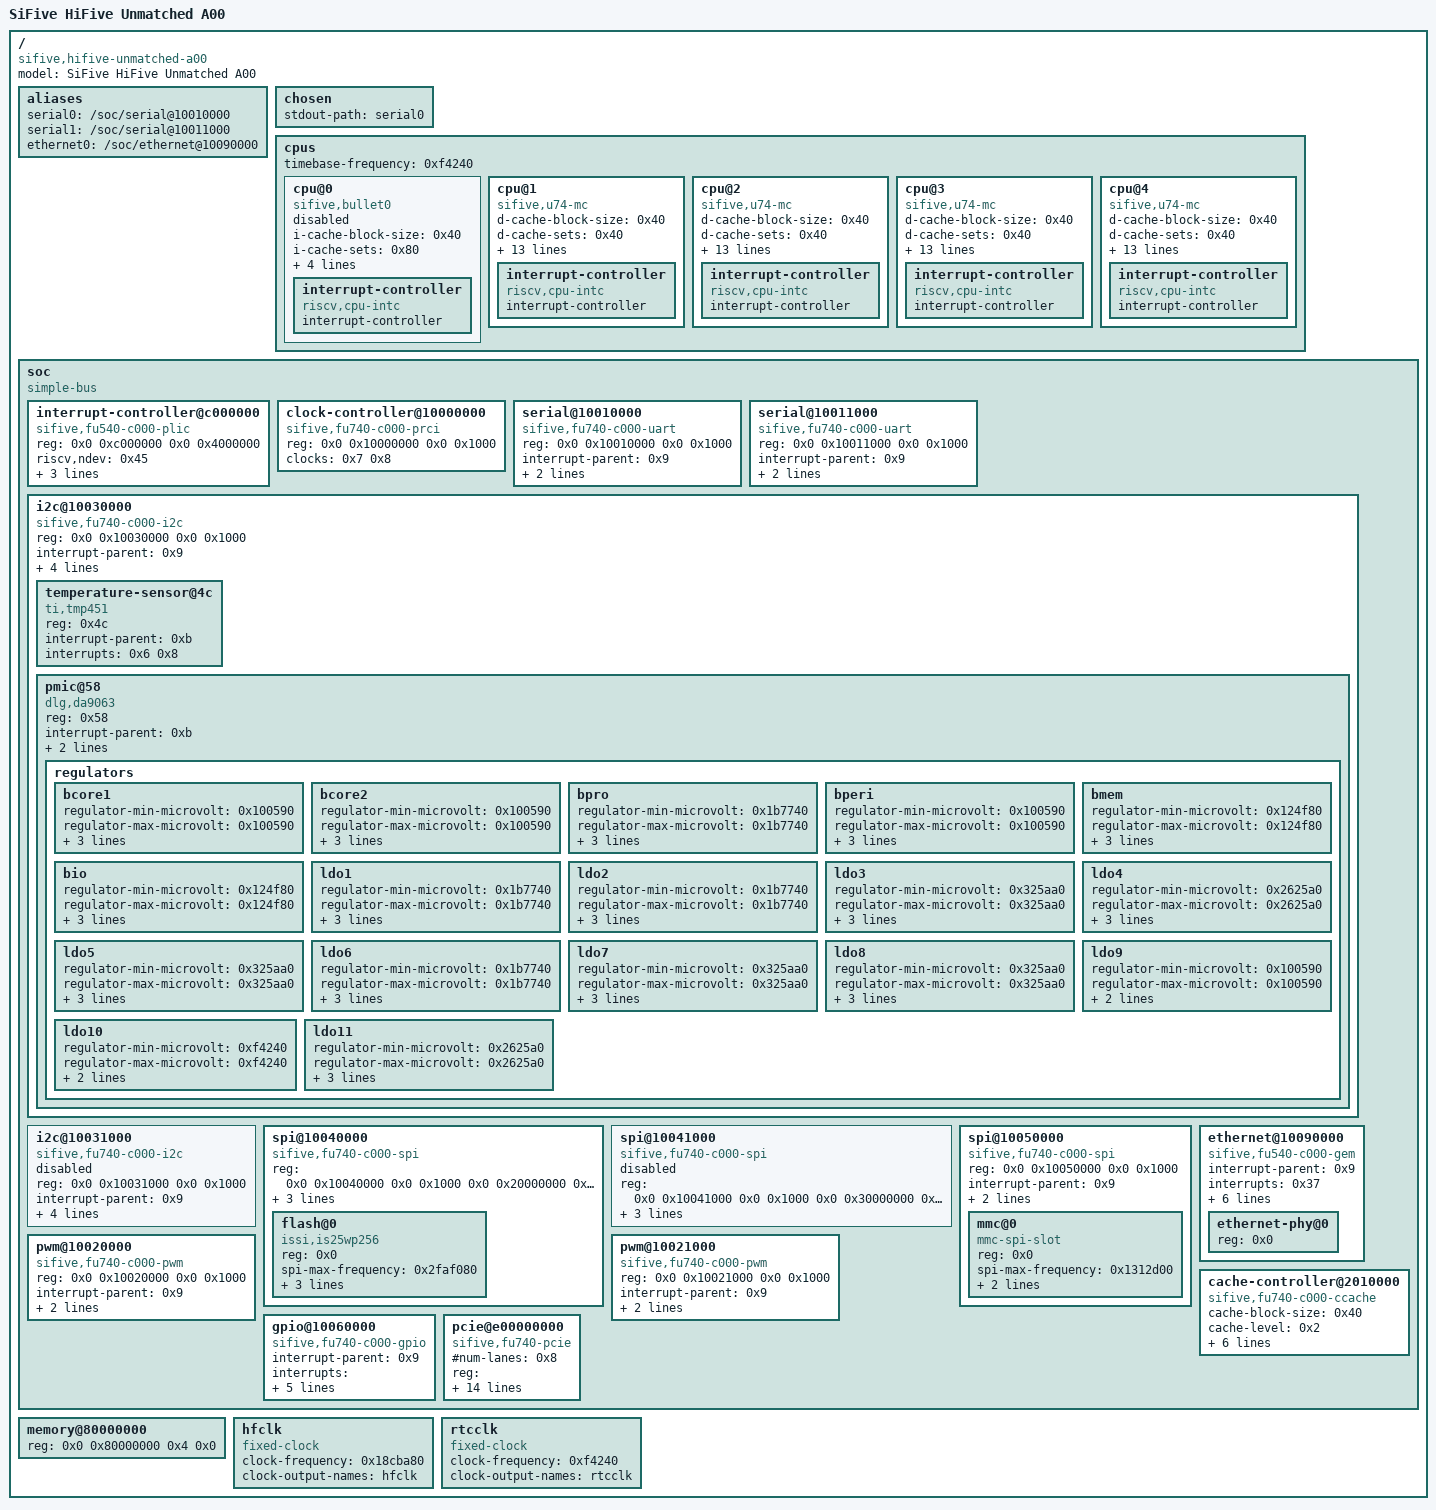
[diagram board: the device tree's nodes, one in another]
/dts-v1/;

/ {
	#address-cells = <0x2>;
	#size-cells = <0x2>;
	compatible = "sifive,hifive-unmatched-a00", "sifive,fu740-c000", "sifive,fu740";
	model = "SiFive HiFive Unmatched A00";

	aliases {
		serial0 = "/soc/serial@10010000";
		serial1 = "/soc/serial@10011000";
		ethernet0 = "/soc/ethernet@10090000";
	};

	chosen {
		stdout-path = "serial0";
	};

	cpus {
		#address-cells = <0x1>;
		#size-cells = <0x0>;
		timebase-frequency = <0xf4240>;

		cpu@0 {
			compatible = "sifive,bullet0", "riscv";
			device_type = "cpu";
			i-cache-block-size = <0x40>;
			i-cache-sets = <0x80>;
			i-cache-size = <0x4000>;
			next-level-cache = <0x1>;
			reg = <0x0>;
			riscv,isa = "rv64imac";
			status = "disabled";

			interrupt-controller {
				#interrupt-cells = <0x1>;
				compatible = "riscv,cpu-intc";
				interrupt-controller;
				phandle = <0x2>;
			};
		};

		cpu@1 {
			compatible = "sifive,u74-mc", "sifive,bullet0", "riscv";
			d-cache-block-size = <0x40>;
			d-cache-sets = <0x40>;
			d-cache-size = <0x8000>;
			d-tlb-sets = <0x1>;
			d-tlb-size = <0x28>;
			device_type = "cpu";
			i-cache-block-size = <0x40>;
			i-cache-sets = <0x80>;
			i-cache-size = <0x8000>;
			i-tlb-sets = <0x1>;
			i-tlb-size = <0x28>;
			mmu-type = "riscv,sv39";
			next-level-cache = <0x1>;
			reg = <0x1>;
			riscv,isa = "rv64imafdc";
			tlb-split;

			interrupt-controller {
				#interrupt-cells = <0x1>;
				compatible = "riscv,cpu-intc";
				interrupt-controller;
				phandle = <0x3>;
			};
		};

		cpu@2 {
			compatible = "sifive,u74-mc", "sifive,bullet0", "riscv";
			d-cache-block-size = <0x40>;
			d-cache-sets = <0x40>;
			d-cache-size = <0x8000>;
			d-tlb-sets = <0x1>;
			d-tlb-size = <0x28>;
			device_type = "cpu";
			i-cache-block-size = <0x40>;
			i-cache-sets = <0x80>;
			i-cache-size = <0x8000>;
			i-tlb-sets = <0x1>;
			i-tlb-size = <0x28>;
			mmu-type = "riscv,sv39";
			next-level-cache = <0x1>;
			reg = <0x2>;
			riscv,isa = "rv64imafdc";
			tlb-split;

			interrupt-controller {
				#interrupt-cells = <0x1>;
				compatible = "riscv,cpu-intc";
				interrupt-controller;
				phandle = <0x4>;
			};
		};

		cpu@3 {
			compatible = "sifive,u74-mc", "sifive,bullet0", "riscv";
			d-cache-block-size = <0x40>;
			d-cache-sets = <0x40>;
			d-cache-size = <0x8000>;
			d-tlb-sets = <0x1>;
			d-tlb-size = <0x28>;
			device_type = "cpu";
			i-cache-block-size = <0x40>;
			i-cache-sets = <0x80>;
			i-cache-size = <0x8000>;
			i-tlb-sets = <0x1>;
			i-tlb-size = <0x28>;
			mmu-type = "riscv,sv39";
			next-level-cache = <0x1>;
			reg = <0x3>;
			riscv,isa = "rv64imafdc";
			tlb-split;

			interrupt-controller {
				#interrupt-cells = <0x1>;
				compatible = "riscv,cpu-intc";
				interrupt-controller;
				phandle = <0x5>;
			};
		};

		cpu@4 {
			compatible = "sifive,u74-mc", "sifive,bullet0", "riscv";
			d-cache-block-size = <0x40>;
			d-cache-sets = <0x40>;
			d-cache-size = <0x8000>;
			d-tlb-sets = <0x1>;
			d-tlb-size = <0x28>;
			device_type = "cpu";
			i-cache-block-size = <0x40>;
			i-cache-sets = <0x80>;
			i-cache-size = <0x8000>;
			i-tlb-sets = <0x1>;
			i-tlb-size = <0x28>;
			mmu-type = "riscv,sv39";
			next-level-cache = <0x1>;
			reg = <0x4>;
			riscv,isa = "rv64imafdc";
			tlb-split;

			interrupt-controller {
				#interrupt-cells = <0x1>;
				compatible = "riscv,cpu-intc";
				interrupt-controller;
				phandle = <0x6>;
			};
		};
	};

	soc {
		#address-cells = <0x2>;
		#size-cells = <0x2>;
		compatible = "simple-bus";
		ranges;

		interrupt-controller@c000000 {
			#interrupt-cells = <0x1>;
			#address-cells = <0x0>;
			compatible = "sifive,fu540-c000-plic", "sifive,plic-1.0.0";
			reg = <0x0 0xc000000 0x0 0x4000000>;
			riscv,ndev = <0x45>;
			interrupt-controller;
			interrupts-extended = <0x2 0xffffffff 0x3 0xffffffff 0x3 0x9 0x4 0xffffffff 0x4 0x9 0x5 0xffffffff 0x5 0x9 0x6 0xffffffff 0x6 0x9>;
			phandle = <0x9>;
		};

		clock-controller@10000000 {
			compatible = "sifive,fu740-c000-prci";
			reg = <0x0 0x10000000 0x0 0x1000>;
			clocks = <0x7 0x8>;
			#clock-cells = <0x1>;
			#reset-cells = <0x1>;
			phandle = <0xa>;
		};

		serial@10010000 {
			compatible = "sifive,fu740-c000-uart", "sifive,uart0";
			reg = <0x0 0x10010000 0x0 0x1000>;
			interrupt-parent = <0x9>;
			interrupts = <0x27>;
			clocks = <0xa 0x7>;
			status = "okay";
		};

		serial@10011000 {
			compatible = "sifive,fu740-c000-uart", "sifive,uart0";
			reg = <0x0 0x10011000 0x0 0x1000>;
			interrupt-parent = <0x9>;
			interrupts = <0x28>;
			clocks = <0xa 0x7>;
			status = "okay";
		};

		i2c@10030000 {
			compatible = "sifive,fu740-c000-i2c", "sifive,i2c0";
			reg = <0x0 0x10030000 0x0 0x1000>;
			interrupt-parent = <0x9>;
			interrupts = <0x34>;
			clocks = <0xa 0x7>;
			reg-shift = <0x2>;
			reg-io-width = <0x1>;
			#address-cells = <0x1>;
			#size-cells = <0x0>;
			status = "okay";

			temperature-sensor@4c {
				compatible = "ti,tmp451";
				reg = <0x4c>;
				interrupt-parent = <0xb>;
				interrupts = <0x6 0x8>;
			};

			pmic@58 {
				compatible = "dlg,da9063";
				reg = <0x58>;
				interrupt-parent = <0xb>;
				interrupts = <0x1 0x8>;
				interrupt-controller;

				regulators {

					bcore1 {
						regulator-min-microvolt = <0x100590>;
						regulator-max-microvolt = <0x100590>;
						regulator-min-microamp = <0x4c4b40>;
						regulator-max-microamp = <0x4c4b40>;
						regulator-always-on;
					};

					bcore2 {
						regulator-min-microvolt = <0x100590>;
						regulator-max-microvolt = <0x100590>;
						regulator-min-microamp = <0x4c4b40>;
						regulator-max-microamp = <0x4c4b40>;
						regulator-always-on;
					};

					bpro {
						regulator-min-microvolt = <0x1b7740>;
						regulator-max-microvolt = <0x1b7740>;
						regulator-min-microamp = <0x2625a0>;
						regulator-max-microamp = <0x2625a0>;
						regulator-always-on;
					};

					bperi {
						regulator-min-microvolt = <0x100590>;
						regulator-max-microvolt = <0x100590>;
						regulator-min-microamp = <0x16e360>;
						regulator-max-microamp = <0x16e360>;
						regulator-always-on;
					};

					bmem {
						regulator-min-microvolt = <0x124f80>;
						regulator-max-microvolt = <0x124f80>;
						regulator-min-microamp = <0x2dc6c0>;
						regulator-max-microamp = <0x2dc6c0>;
						regulator-always-on;
					};

					bio {
						regulator-min-microvolt = <0x124f80>;
						regulator-max-microvolt = <0x124f80>;
						regulator-min-microamp = <0x2dc6c0>;
						regulator-max-microamp = <0x2dc6c0>;
						regulator-always-on;
					};

					ldo1 {
						regulator-min-microvolt = <0x1b7740>;
						regulator-max-microvolt = <0x1b7740>;
						regulator-min-microamp = <0x186a0>;
						regulator-max-microamp = <0x186a0>;
						regulator-always-on;
					};

					ldo2 {
						regulator-min-microvolt = <0x1b7740>;
						regulator-max-microvolt = <0x1b7740>;
						regulator-min-microamp = <0x30d40>;
						regulator-max-microamp = <0x30d40>;
						regulator-always-on;
					};

					ldo3 {
						regulator-min-microvolt = <0x325aa0>;
						regulator-max-microvolt = <0x325aa0>;
						regulator-min-microamp = <0x30d40>;
						regulator-max-microamp = <0x30d40>;
						regulator-always-on;
					};

					ldo4 {
						regulator-min-microvolt = <0x2625a0>;
						regulator-max-microvolt = <0x2625a0>;
						regulator-min-microamp = <0x30d40>;
						regulator-max-microamp = <0x30d40>;
						regulator-always-on;
					};

					ldo5 {
						regulator-min-microvolt = <0x325aa0>;
						regulator-max-microvolt = <0x325aa0>;
						regulator-min-microamp = <0x186a0>;
						regulator-max-microamp = <0x186a0>;
						regulator-always-on;
					};

					ldo6 {
						regulator-min-microvolt = <0x1b7740>;
						regulator-max-microvolt = <0x1b7740>;
						regulator-min-microamp = <0x30d40>;
						regulator-max-microamp = <0x30d40>;
						regulator-always-on;
					};

					ldo7 {
						regulator-min-microvolt = <0x325aa0>;
						regulator-max-microvolt = <0x325aa0>;
						regulator-min-microamp = <0x30d40>;
						regulator-max-microamp = <0x30d40>;
						regulator-always-on;
					};

					ldo8 {
						regulator-min-microvolt = <0x325aa0>;
						regulator-max-microvolt = <0x325aa0>;
						regulator-min-microamp = <0x30d40>;
						regulator-max-microamp = <0x30d40>;
						regulator-always-on;
					};

					ldo9 {
						regulator-min-microvolt = <0x100590>;
						regulator-max-microvolt = <0x100590>;
						regulator-min-microamp = <0x30d40>;
						regulator-max-microamp = <0x30d40>;
					};

					ldo10 {
						regulator-min-microvolt = <0xf4240>;
						regulator-max-microvolt = <0xf4240>;
						regulator-min-microamp = <0x493e0>;
						regulator-max-microamp = <0x493e0>;
					};

					ldo11 {
						regulator-min-microvolt = <0x2625a0>;
						regulator-max-microvolt = <0x2625a0>;
						regulator-min-microamp = <0x493e0>;
						regulator-max-microamp = <0x493e0>;
						regulator-always-on;
					};
				};
			};
		};

		i2c@10031000 {
			compatible = "sifive,fu740-c000-i2c", "sifive,i2c0";
			reg = <0x0 0x10031000 0x0 0x1000>;
			interrupt-parent = <0x9>;
			interrupts = <0x35>;
			clocks = <0xa 0x7>;
			reg-shift = <0x2>;
			reg-io-width = <0x1>;
			#address-cells = <0x1>;
			#size-cells = <0x0>;
			status = "disabled";
		};

		spi@10040000 {
			compatible = "sifive,fu740-c000-spi", "sifive,spi0";
			reg = <0x0 0x10040000 0x0 0x1000 0x0 0x20000000 0x0 0x10000000>;
			interrupt-parent = <0x9>;
			interrupts = <0x29>;
			clocks = <0xa 0x7>;
			#address-cells = <0x1>;
			#size-cells = <0x0>;
			status = "okay";

			flash@0 {
				compatible = "issi,is25wp256", "jedec,spi-nor";
				reg = <0x0>;
				spi-max-frequency = <0x2faf080>;
				m25p,fast-read;
				spi-tx-bus-width = <0x4>;
				spi-rx-bus-width = <0x4>;
			};
		};

		spi@10041000 {
			compatible = "sifive,fu740-c000-spi", "sifive,spi0";
			reg = <0x0 0x10041000 0x0 0x1000 0x0 0x30000000 0x0 0x10000000>;
			interrupt-parent = <0x9>;
			interrupts = <0x2a>;
			clocks = <0xa 0x7>;
			#address-cells = <0x1>;
			#size-cells = <0x0>;
			status = "disabled";
		};

		spi@10050000 {
			compatible = "sifive,fu740-c000-spi", "sifive,spi0";
			reg = <0x0 0x10050000 0x0 0x1000>;
			interrupt-parent = <0x9>;
			interrupts = <0x2b>;
			clocks = <0xa 0x7>;
			#address-cells = <0x1>;
			#size-cells = <0x0>;
			status = "okay";

			mmc@0 {
				compatible = "mmc-spi-slot";
				reg = <0x0>;
				spi-max-frequency = <0x1312d00>;
				voltage-ranges = <0xce4 0xce4>;
				disable-wp;
			};
		};

		ethernet@10090000 {
			compatible = "sifive,fu540-c000-gem";
			interrupt-parent = <0x9>;
			interrupts = <0x37>;
			reg = <0x0 0x10090000 0x0 0x2000 0x0 0x100a0000 0x0 0x1000>;
			local-mac-address = [00 00 00 00 00 00];
			clock-names = "pclk", "hclk";
			clocks = <0xa 0x2 0xa 0x2>;
			#address-cells = <0x1>;
			#size-cells = <0x0>;
			status = "okay";
			phy-mode = "gmii";
			phy-handle = <0xc>;

			ethernet-phy@0 {
				reg = <0x0>;
				phandle = <0xc>;
			};
		};

		pwm@10020000 {
			compatible = "sifive,fu740-c000-pwm", "sifive,pwm0";
			reg = <0x0 0x10020000 0x0 0x1000>;
			interrupt-parent = <0x9>;
			interrupts = <0x2c 0x2d 0x2e 0x2f>;
			clocks = <0xa 0x7>;
			#pwm-cells = <0x3>;
			status = "okay";
		};

		pwm@10021000 {
			compatible = "sifive,fu740-c000-pwm", "sifive,pwm0";
			reg = <0x0 0x10021000 0x0 0x1000>;
			interrupt-parent = <0x9>;
			interrupts = <0x30 0x31 0x32 0x33>;
			clocks = <0xa 0x7>;
			#pwm-cells = <0x3>;
			status = "okay";
		};

		cache-controller@2010000 {
			compatible = "sifive,fu740-c000-ccache", "cache";
			cache-block-size = <0x40>;
			cache-level = <0x2>;
			cache-sets = <0x800>;
			cache-size = <0x200000>;
			cache-unified;
			interrupt-parent = <0x9>;
			interrupts = <0x13 0x15 0x16 0x14>;
			reg = <0x0 0x2010000 0x0 0x1000>;
			phandle = <0x1>;
		};

		gpio@10060000 {
			compatible = "sifive,fu740-c000-gpio", "sifive,gpio0";
			interrupt-parent = <0x9>;
			interrupts = <0x17 0x18 0x19 0x1a 0x1b 0x1c 0x1d 0x1e 0x1f 0x20 0x21 0x22 0x23 0x24 0x25 0x26>;
			reg = <0x0 0x10060000 0x0 0x1000>;
			gpio-controller;
			#gpio-cells = <0x2>;
			interrupt-controller;
			#interrupt-cells = <0x2>;
			clocks = <0xa 0x7>;
			status = "okay";
			phandle = <0xb>;
		};

		pcie@e00000000 {
			#address-cells = <0x3>;
			#interrupt-cells = <0x1>;
			#num-lanes = <0x8>;
			#size-cells = <0x2>;
			compatible = "sifive,fu740-pcie";
			reg = <0xe 0x0 0x1 0x0 0xd 0xf0000000 0x0 0x10000000 0x0 0x100d0000 0x0 0x1000>;
			reg-names = "dbi", "config", "mgmt";
			device_type = "pci";
			dma-coherent;
			bus-range = <0x0 0xff>;
			ranges = <0x81000000 0x0 0x60080000 0x0 0x60080000 0x0 0x10000 0x82000000 0x0 0x60090000 0x0 0x60090000 0x0 0xff70000 0x82000000 0x0 0x70000000 0x0 0x70000000 0x0 0x1000000 0xc3000000 0x20 0x0 0x20 0x0 0x20 0x0>;
			num-lanes = <0x8>;
			interrupts = <0x38 0x39 0x3a 0x3b 0x3c 0x3d 0x3e 0x3f 0x40>;
			interrupt-names = "msi", "inta", "intb", "intc", "intd";
			interrupt-parent = <0x9>;
			interrupt-map-mask = <0x0 0x0 0x0 0x7>;
			interrupt-map = <0x0 0x0 0x0 0x1 0x9 0x39 0x0 0x0 0x0 0x2 0x9 0x3a 0x0 0x0 0x0 0x3 0x9 0x3b 0x0 0x0 0x0 0x4 0x9 0x3c>;
			clock-names = "pcie_aux";
			clocks = <0xa 0x8>;
			pwren-gpios = <0xb 0x5 0x0>;
			perstn-gpios = <0xb 0x8 0x0>;
			resets = <0xa 0x4>;
			status = "okay";
		};
	};

	memory@80000000 {
		device_type = "memory";
		reg = <0x0 0x80000000 0x4 0x0>;
	};

	hfclk {
		#clock-cells = <0x0>;
		compatible = "fixed-clock";
		clock-frequency = <0x18cba80>;
		clock-output-names = "hfclk";
		phandle = <0x7>;
	};

	rtcclk {
		#clock-cells = <0x0>;
		compatible = "fixed-clock";
		clock-frequency = <0xf4240>;
		clock-output-names = "rtcclk";
		phandle = <0x8>;
	};
};
